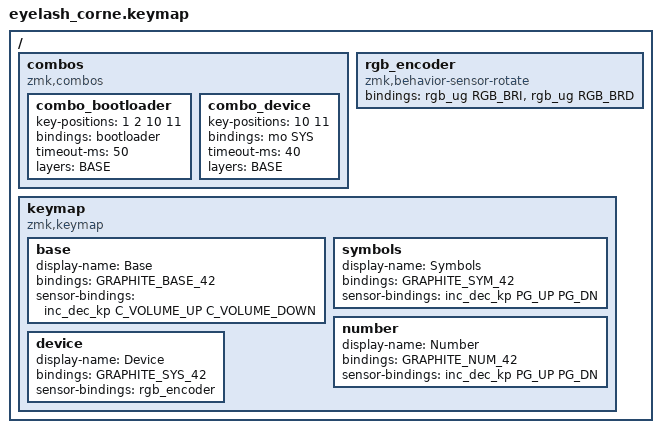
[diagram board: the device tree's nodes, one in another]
#include <behaviors.dtsi>
#include <dt-bindings/zmk/bt.h>
#include <dt-bindings/zmk/keys.h>
#include <dt-bindings/zmk/mouse.h>
#include <dt-bindings/zmk/outputs.h>
#include <dt-bindings/zmk/pointing.h>
#include <dt-bindings/zmk/rgb.h>

#include "../../../config/graphite.dtsi"

/ {
    combos {
        compatible = "zmk,combos";

        // U+J+B+L: bootloader
        combo_bootloader {
            key-positions = <1 2 10 11>;
            bindings = <&bootloader>;
            timeout-ms = <50>;
            layers = <BASE>;
        };

        // U+J: hold for Device layer
        combo_device {
            key-positions = <10 11>;
            bindings = <&mo SYS>;
            timeout-ms = <40>;
            layers = <BASE>;
        };
    };

    rgb_encoder: rgb_encoder {
        compatible = "zmk,behavior-sensor-rotate";
        #sensor-binding-cells = <0>;
        bindings = <&rgb_ug RGB_BRI>, <&rgb_ug RGB_BRD>;
    };

    keymap {
        compatible = "zmk,keymap";

        base {
            display-name = "Base";
            bindings = < GRAPHITE_BASE_42 >;
            sensor-bindings = <&inc_dec_kp C_VOLUME_UP C_VOLUME_DOWN>;
        };

        symbols {
            display-name = "Symbols";
            bindings = < GRAPHITE_SYM_42 >;
            sensor-bindings = <&inc_dec_kp PG_UP PG_DN>;
        };

        number {
            display-name = "Number";
            bindings = < GRAPHITE_NUM_42 >;
            sensor-bindings = <&inc_dec_kp PG_UP PG_DN>;
        };

        device {
            display-name = "Device";
            bindings = < GRAPHITE_SYS_42 >;
            sensor-bindings = <&rgb_encoder>;
        };
    };
};
